# STM32L562xx register map
File version: 1.0
Registers are 32-bit, read-write, reset 0x0 unless marked. A register's access mark holds for its fields unless they carry their own. Offsets are from the block's base; [hi:lo] are bit positions; {n}, {i} and the like mark numbered series.

## OPAMP2 — Operational Amplifier (OPAMP)
Base 0x40007810
Same registers: OPAMP2_S 0x50007810
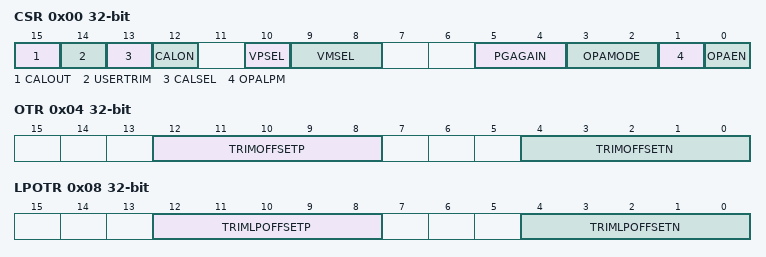
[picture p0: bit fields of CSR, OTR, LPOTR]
0x00 CSR — OPAMP control/status register
  [15] CALOUT — Operational amplifier2 calibration output
  [14] USERTRIM — User trimming enable
  [13] CALSEL — Calibration selection
  [12] CALON — Calibration mode enable
  [10] VPSEL — Non inverted input selection
  [9:8] VMSEL — Inverting input selection
  [5:4] PGAGAIN — Operational amplifier2 Programmable amplifier gain value
  [3:2] OPAMODE — Operational amplifier2 PGA mode
  [1] OPALPM — Operational amplifier2 Low Power Mode
  [0] OPAEN — Operational amplifier2 Enable
0x04 OTR — OPAMP
  [12:8] TRIMOFFSETP — Trim for PMOS differential pairs
  [4:0] TRIMOFFSETN — Trim for NMOS differential pairs
0x08 LPOTR — OPAMP
  [12:8] TRIMLPOFFSETP — Trim for PMOS differential pairs
  [4:0] TRIMLPOFFSETN — Trim for NMOS differential pairs

## FDCAN_CONFIG — FD Controller Area Network Configuration
Base 0x4000A500
Same registers: FDCAN_CONFIG_S 0x5000A500
0x00 CKDIV — FDCAN clock divider register
  [3:0] PDIV — Input Clock Divider
0x204 OPTR — FDCAN option register
  [31:0] OPTR — Option Register

## USB — Universal Serial Bus Full Speed Device
Base 0x4000D400
Same registers: USB_S 0x5000D400
{0x0+4i} EP{i}R 16-bit (i=0..7) — USB Endpoint {i} register
0x40 CNTR 16-bit — Control register
0x44 ISTR 16-bit — Interrupt status register
0x48 FNR 16-bit — Frame number register
0x4C DADDR 16-bit — Device address register
0x50 BTABLE 16-bit — Buffer Table address register
0x54 LPMCSR 16-bit — LPM Control and Status register
0x58 BCDR 16-bit — Battery Charging detector register

## SYSCFG — System configuration controller
Base 0x40010000
Same registers: SYSCFG_S 0x50010000
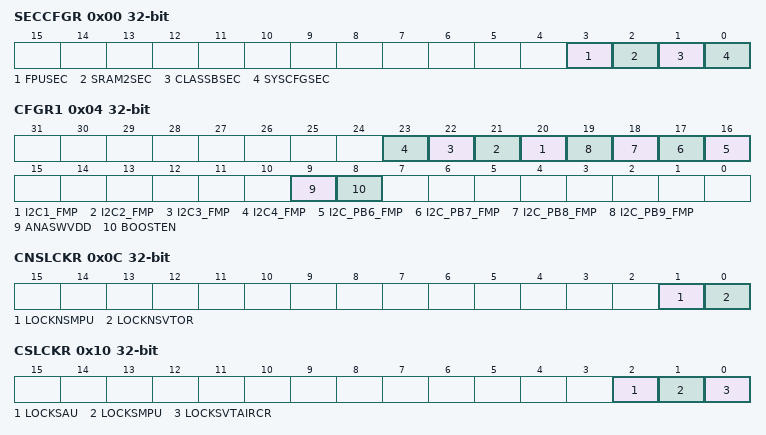
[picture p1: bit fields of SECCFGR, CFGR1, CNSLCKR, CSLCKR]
0x00 SECCFGR — SYSCFG secure configuration register
  [3] FPUSEC — FPU SYSCFG security enable
  [2] SRAM2SEC — SRAM2 SYSCFG security enable
  [1] CLASSBSEC — ClassB SYSCFG security enable
  [0] SYSCFGSEC — SYSCFG clock control security enable
0x04 CFGR1 — SYSCFG configuration register 1
  [n+19] I2C{n}_FMP (n=1..4) — I2C{n} Fast mode plus
  [n+10] I2C_PB{n}_FMP (n=6..9) — I2C PB{n} Fast mode plus
  [9] ANASWVDD — GPIO analog switch control voltage selection enable
  [8] BOOSTEN — I/O analog switch voltage booster enable
0x08 FPUIMR — SYSCFG FPU interrupt mask register
  [5:0] FPU_IE — All FPU interrupts enable
0x0C CNSLCKR — SYSCFG CPU non-secure lock register
  [1] LOCKNSMPU — Disable Non-Secure MPU registers writes by SW or debug agent
  [0] LOCKNSVTOR — Disable VTOR_NS register writes by SW or debug agent
0x10 CSLCKR — SYSCFG CPU secure lock register
  [2] LOCKSAU — Disable changes to SAU registers
  [1] LOCKSMPU — Disable changes to the secure MPU registers writes by SW or debug agent
  [0] LOCKSVTAIRCR — Disable changes to the secure vector table address, handling of system faults
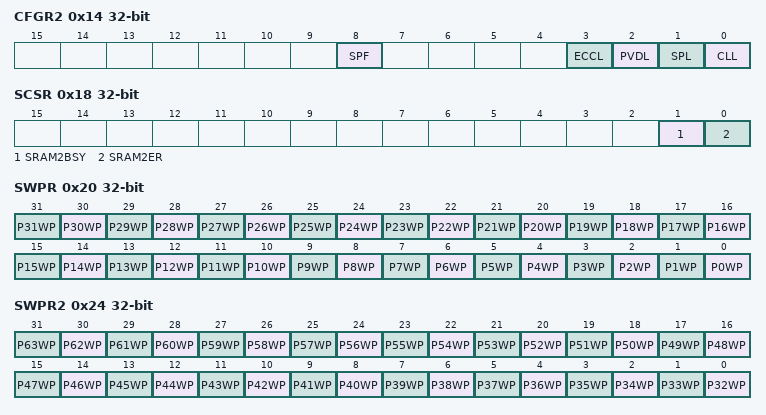
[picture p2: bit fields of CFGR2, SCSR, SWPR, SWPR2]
0x14 CFGR2 — SYSCFG configuration register 2
  [8] SPF — SRAM Parity Flag
  [3] ECCL — ECC Lock
  [2] PVDL — PVD Lock
  [1] SPL — SRAM Parity Lock
  [0] CLL — Core Lockup Lock
0x18 SCSR — SYSCFG SRAM2 control and status register
  [1] SRAM2BSY — SRAM2 Erase Ongoing
  [0] SRAM2ER — SRAM2 Erase Request
0x1C SKR — SYSCFG SRAM2 key register
  [7:0] KEY — SRAM2 write protection key for software erase
0x20 SWPR — SYSCFG SRAM2 write protection register 1
  [n] P{n}WP (n=0..31) — SRAM2 Write protection page {n}
0x24 SWPR2 — SYSCFG SRAM2 write protection register 2
  [n-32] P{n}WP (n=32..63) — SRAM2 Write protection page {n}
0x2C RSSCMDR — SYSCFG RSS command register
  [15:0] RSSCMD — RSS commands

## VREFBUF
Base 0x40010100
Same registers: VREFBUF_S 0x50010100
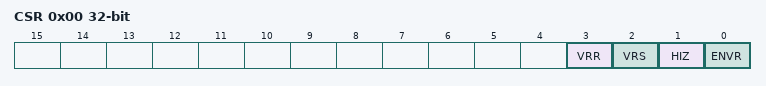
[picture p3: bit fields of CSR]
0x00 CSR — VREFBUF control and status register
  [3] VRR — Voltage reference buffer ready
  [2] VRS — Voltage reference scale
    0=SCALE0 (Voltage reference scale 0 (VREF_OUT1)); 1=SCALE1 (Voltage reference scale 1 (VREF_OUT2))
  [1] HIZ — High impedance mode
  [0] ENVR — Voltage reference buffer enable
0x04 CCR — VREFBUF calibration and control register
  [5:0] TRIM — TRIM[5:0] bits (Trimming code)
